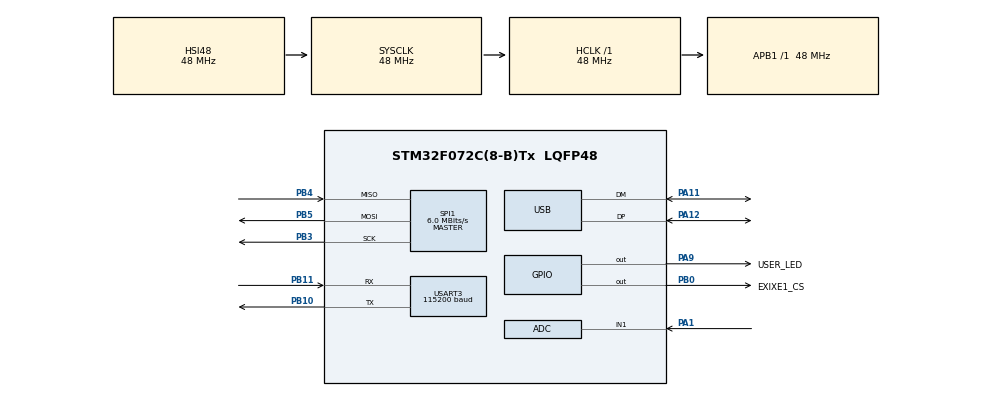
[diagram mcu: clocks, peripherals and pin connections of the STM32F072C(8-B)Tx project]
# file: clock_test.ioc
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ADC.ClockPrescaler=ADC_CLOCK_ASYNC_DIV1
ADC.ContinuousConvMode=DISABLE
ADC.DMAContinuousRequests=DISABLE
ADC.DataAlign=ADC_DATAALIGN_RIGHT
ADC.DiscontinuousConvMode=DISABLE
ADC.EOCSelection=ADC_EOC_SINGLE_CONV
ADC.EnableAnalogWatchDog=false
ADC.ExternalTrigConv=ADC_SOFTWARE_START
ADC.ExternalTrigConvEdge=ADC_EXTERNALTRIGCONVEDGE_NONE
ADC.LowPowerAutoPowerOff=DISABLE
ADC.LowPowerAutoWait=DISABLE
ADC.Overrun=ADC_OVR_DATA_PRESERVED
ADC.Resolution=ADC_RESOLUTION_12B
ADC.SamplingTime=ADC_SAMPLETIME_239CYCLES_5
ADC.ScanConvMode=ADC_SCAN_DIRECTION_FORWARD
FREERTOS.HEAP_NUMBER=1
FREERTOS.Tasks01=defaultTask,-3,64,StartDefaultTask,Default,NULL,Dynamic,NULL,NULL
FREERTOS.configENABLE_BACKWARD_COMPATIBILITY=0
FREERTOS.configMINIMAL_STACK_SIZE=64
FREERTOS.configTOTAL_HEAP_SIZE=4096
FREERTOS.configUSE_MUTEXES=0
FREERTOS.configUSE_TASK_NOTIFICATIONS=0
Mcu.Family=STM32F0
Mcu.Name=STM32F072C(8-B)Tx
Mcu.Package=LQFP48
NVIC.TIM7_IRQn=true\:0\:0\:false\:false\:true\:false
NVIC.TimeBase=TIM7_IRQn
NVIC.TimeBaseIP=TIM7
NVIC.USB_IRQn=true\:3\:0\:false\:false\:true\:true
PA1.Mode=IN1
PA1.Signal=ADC_IN1
PA11.Mode=Device
PA11.Signal=USB_DM
PA12.Mode=Device
PA12.Signal=USB_DP
PA13.Mode=Serial_Wire
PA13.Signal=SYS_SWDIO
PA14.Mode=Serial_Wire
PA14.Signal=SYS_SWCLK
PA9.GPIO_Label=USER_LED
PA9.PinState=GPIO_PIN_SET
PA9.Signal=GPIO_Output
PB0.GPIO_Label=EXIXE1_CS
PB0.PinState=GPIO_PIN_SET
PB0.Signal=GPIO_Output
PB10.Mode=Asynchronous
PB10.Signal=USART3_TX
PB11.Mode=Asynchronous
PB11.Signal=USART3_RX
PB3.Mode=Full_Duplex_Master
PB3.Signal=SPI1_SCK
PB4.Mode=Full_Duplex_Master
PB4.Signal=SPI1_MISO
PB5.Mode=Full_Duplex_Master
PB5.Signal=SPI1_MOSI
ProjectManager.HeapSize=0x200
ProjectManager.StackSize=0x400
ProjectManager.TargetToolchain=MDK-ARM V5
RCC.AHBFreq_Value=48000000
RCC.APB1Freq_Value=48000000
RCC.APB1TimFreq_Value=48000000
RCC.HCLKFreq_Value=48000000
RCC.PLLMUL=RCC_PLL_MUL6
RCC.SYSCLKFreq_VALUE=48000000
RCC.SYSCLKSource=RCC_SYSCLKSOURCE_HSI48
SPI1.BaudRatePrescaler=SPI_BAUDRATEPRESCALER_8
SPI1.CalculateBaudRate=6.0 MBits/s
SPI1.DataSize=SPI_DATASIZE_8BIT
SPI1.Direction=SPI_DIRECTION_2LINES
SPI1.Mode=SPI_MODE_MASTER
SPI1.VirtualType=VM_MASTER
TIM2.Prescaler=47
USART3.BaudRate=115200
USART3.VirtualMode-Asynchronous=VM_ASYNC
USART3.WordLength=WORDLENGTH_8B
USB_DEVICE.CLASS_NAME_FS=CDC
USB_DEVICE.VirtualMode=Cdc
USB_DEVICE.VirtualModeFS=Cdc_FS
VP_FREERTOS_VS_ENABLE.Mode=Enabled
VP_SYS_VS_tim7.Mode=TIM7
VP_TIM2_VS_ClockSourceINT.Mode=Internal
VP_USB_DEVICE_VS_USB_DEVICE_CDC_FS.Mode=CDC_FS
board=clock_test

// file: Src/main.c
/**
  ******************************************************************************
  * File Name          : main.c
  * Description        : Main program body
  ******************************************************************************
  *
  * Copyright (c) 2017 STMicroelectronics International N.V.
  * All rights reserved.
  *
  * Redistribution and use in source and binary forms, with or without
  * modification, are permitted, provided that the following conditions are met:
  *
  * 1. Redistribution of source code must retain the above copyright notice,
  *    this list of conditions and the following disclaimer.
  * 2. Redistributions in binary form must reproduce the above copyright notice,
  *    this list of conditions and the following disclaimer in the documentation
  *    and/or other materials provided with the distribution.
  * 3. Neither the name of STMicroelectronics nor the names of other
  *    contributors to this software may be used to endorse or promote products
  *    derived from this software without specific written permission.
  * 4. This software, including modifications and/or derivative works of this
  *    software, must execute solely and exclusively on microcontroller or
  *    microprocessor devices manufactured by or for STMicroelectronics.
  * 5. Redistribution and use of this software other than as permitted under
  *    this license is void and will automatically terminate your rights under
  *    this license.
  *
  * THIS SOFTWARE IS PROVIDED BY STMICROELECTRONICS AND CONTRIBUTORS "AS IS"
  * AND ANY EXPRESS, IMPLIED OR STATUTORY WARRANTIES, INCLUDING, BUT NOT
  * LIMITED TO, THE IMPLIED WARRANTIES OF MERCHANTABILITY, FITNESS FOR A
  * PARTICULAR PURPOSE AND NON-INFRINGEMENT OF THIRD PARTY INTELLECTUAL PROPERTY
  * RIGHTS ARE DISCLAIMED TO THE FULLEST EXTENT PERMITTED BY LAW. IN NO EVENT
  * SHALL STMICROELECTRONICS OR CONTRIBUTORS BE LIABLE FOR ANY DIRECT, INDIRECT,
  * INCIDENTAL, SPECIAL, EXEMPLARY, OR CONSEQUENTIAL DAMAGES (INCLUDING, BUT NOT
  * LIMITED TO, PROCUREMENT OF SUBSTITUTE GOODS OR SERVICES; LOSS OF USE, DATA,
  * OR PROFITS; OR BUSINESS INTERRUPTION) HOWEVER CAUSED AND ON ANY THEORY OF
  * LIABILITY, WHETHER IN CONTRACT, STRICT LIABILITY, OR TORT (INCLUDING
  * NEGLIGENCE OR OTHERWISE) ARISING IN ANY WAY OUT OF THE USE OF THIS SOFTWARE,
  * EVEN IF ADVISED OF THE POSSIBILITY OF SUCH DAMAGE.
  *
  ******************************************************************************
  */
#include "main.h"
#include "stm32f0xx_hal.h"
#include "cmsis_os.h"
#include "usb_device.h"

/* USER CODE BEGIN Includes */
#include "shared.h"
#include "my_usb.h"
#include "helpers.h"
#include "my_tasks.h"
#include "delay_us.h"
/* USER CODE END Includes */

ADC_HandleTypeDef hadc;

SPI_HandleTypeDef hspi1;

TIM_HandleTypeDef htim2;

UART_HandleTypeDef huart3;

osThreadId defaultTaskHandle;

/* USER CODE BEGIN PV */
/* Private variables ---------------------------------------------------------*/

/* USER CODE END PV */

void SystemClock_Config(void);
void Error_Handler(void);
static void MX_GPIO_Init(void);
static void MX_SPI1_Init(void);
static void MX_USART3_UART_Init(void);
static void MX_ADC_Init(void);
static void MX_TIM2_Init(void);
void StartDefaultTask(void const * argument);

/* USER CODE BEGIN PFP */
/* Private function prototypes -----------------------------------------------*/

/* USER CODE END PFP */

/* USER CODE BEGIN 0 */
// int fputc(int ch, FILE *f)
// {
//   my_usb_putchar((uint8_t)ch);
//   return ch;
// }

int fputc(int ch, FILE *f)
{
    HAL_UART_Transmit(&huart3, (unsigned char *)&ch, 1, 100);
    return ch;
}
/* USER CODE END 0 */

int main(void)
{

  /* MCU Configuration----------------------------------------------------------*/

  /* Reset of all peripherals, Initializes the Flash interface and the Systick. */
  HAL_Init();

  /* Configure the system clock */
  SystemClock_Config();

  /* Initialize all configured peripherals */
  MX_GPIO_Init();
  MX_SPI1_Init();
  MX_USART3_UART_Init();
  MX_ADC_Init();
  MX_TIM2_Init();

  /* USER CODE BEGIN 2 */
  MX_USB_DEVICE_Init();
  my_usb_init();
  delay_us_init(&htim2);
  setup_task();
  /* USER CODE END 2 */

  /* Create the thread(s) */
  /* definition and creation of defaultTask */
  osThreadDef(defaultTask, StartDefaultTask, osPriorityIdle, 0, 64);
  defaultTaskHandle = osThreadCreate(osThread(defaultTask), NULL);

  /* USER CODE BEGIN RTOS_THREADS */
  osThreadDef(animation_task, animation_task_start, osPriorityNormal, 0, 128);
  osThreadCreate(osThread(animation_task), NULL);
  osThreadDef(test_task, test_task_start, osPriorityNormal, 0, 64);
  osThreadCreate(osThread(test_task), NULL);
  /* add threads, ... */
  /* USER CODE END RTOS_THREADS */

  /* Start scheduler */
  osKernelStart();

  /* We should never get here as control is now taken by the scheduler */

  /* Infinite loop */
  while (1)
  {

  }

}

/** System Clock Configuration
*/
void SystemClock_Config(void)
{

  RCC_OscInitTypeDef RCC_OscInitStruct;
  RCC_ClkInitTypeDef RCC_ClkInitStruct;
  RCC_PeriphCLKInitTypeDef PeriphClkInit;

    /**Initializes the CPU, AHB and APB busses clocks
    */
  RCC_OscInitStruct.OscillatorType = RCC_OSCILLATORTYPE_HSI14|RCC_OSCILLATORTYPE_HSI48;
  RCC_OscInitStruct.HSI48State = RCC_HSI48_ON;
  RCC_OscInitStruct.HSI14State = RCC_HSI14_ON;
  RCC_OscInitStruct.HSI14CalibrationValue = 16;
  RCC_OscInitStruct.PLL.PLLState = RCC_PLL_NONE;
  if (HAL_RCC_OscConfig(&RCC_OscInitStruct) != HAL_OK)
  {
    Error_Handler();
  }

    /**Initializes the CPU, AHB and APB busses clocks
    */
  RCC_ClkInitStruct.ClockType = RCC_CLOCKTYPE_HCLK|RCC_CLOCKTYPE_SYSCLK
                              |RCC_CLOCKTYPE_PCLK1;
  RCC_ClkInitStruct.SYSCLKSource = RCC_SYSCLKSOURCE_HSI48;
  RCC_ClkInitStruct.AHBCLKDivider = RCC_SYSCLK_DIV1;
  RCC_ClkInitStruct.APB1CLKDivider = RCC_HCLK_DIV1;

  if (HAL_RCC_ClockConfig(&RCC_ClkInitStruct, FLASH_LATENCY_1) != HAL_OK)
  {
    Error_Handler();
  }

  PeriphClkInit.PeriphClockSelection = RCC_PERIPHCLK_USB;
  PeriphClkInit.UsbClockSelection = RCC_USBCLKSOURCE_HSI48;

  if (HAL_RCCEx_PeriphCLKConfig(&PeriphClkInit) != HAL_OK)
  {
    Error_Handler();
  }

    /**Configure the Systick interrupt time
    */
  HAL_SYSTICK_Config(HAL_RCC_GetHCLKFreq()/1000);

    /**Configure the Systick
    */
  HAL_SYSTICK_CLKSourceConfig(SYSTICK_CLKSOURCE_HCLK);

  /* SysTick_IRQn interrupt configuration */
  HAL_NVIC_SetPriority(SysTick_IRQn, 3, 0);
}

/* ADC init function */
static void MX_ADC_Init(void)
{

  ADC_ChannelConfTypeDef sConfig;

    /**Configure the global features of the ADC (Clock, Resolution, Data Alignment and number of conversion)
    */
  hadc.Instance = ADC1;
  hadc.Init.ClockPrescaler = ADC_CLOCK_ASYNC_DIV1;
  hadc.Init.Resolution = ADC_RESOLUTION_12B;
  hadc.Init.DataAlign = ADC_DATAALIGN_RIGHT;
  hadc.Init.ScanConvMode = ADC_SCAN_DIRECTION_FORWARD;
  hadc.Init.EOCSelection = ADC_EOC_SINGLE_CONV;
  hadc.Init.LowPowerAutoWait = DISABLE;
  hadc.Init.LowPowerAutoPowerOff = DISABLE;
  hadc.Init.ContinuousConvMode = DISABLE;
  hadc.Init.DiscontinuousConvMode = DISABLE;
  hadc.Init.ExternalTrigConv = ADC_SOFTWARE_START;
  hadc.Init.ExternalTrigConvEdge = ADC_EXTERNALTRIGCONVEDGE_NONE;
  hadc.Init.DMAContinuousRequests = DISABLE;
  hadc.Init.Overrun = ADC_OVR_DATA_PRESERVED;
  if (HAL_ADC_Init(&hadc) != HAL_OK)
  {
    Error_Handler();
  }

    /**Configure for the selected ADC regular channel to be converted.
    */
  sConfig.Channel = ADC_CHANNEL_1;
  sConfig.Rank = ADC_RANK_CHANNEL_NUMBER;
  sConfig.SamplingTime = ADC_SAMPLETIME_239CYCLES_5;
  if (HAL_ADC_ConfigChannel(&hadc, &sConfig) != HAL_OK)
  {
    Error_Handler();
  }

}

/* SPI1 init function */
static void MX_SPI1_Init(void)
{

  hspi1.Instance = SPI1;
  hspi1.Init.Mode = SPI_MODE_MASTER;
  hspi1.Init.Direction = SPI_DIRECTION_2LINES;
  hspi1.Init.DataSize = SPI_DATASIZE_8BIT;
  hspi1.Init.CLKPolarity = SPI_POLARITY_LOW;
  hspi1.Init.CLKPhase = SPI_PHASE_1EDGE;
  hspi1.Init.NSS = SPI_NSS_SOFT;
  hspi1.Init.BaudRatePrescaler = SPI_BAUDRATEPRESCALER_8;
  hspi1.Init.FirstBit = SPI_FIRSTBIT_MSB;
  hspi1.Init.TIMode = SPI_TIMODE_DISABLE;
  hspi1.Init.CRCCalculation = SPI_CRCCALCULATION_DISABLE;
  hspi1.Init.CRCPolynomial = 7;
  hspi1.Init.CRCLength = SPI_CRC_LENGTH_DATASIZE;
  hspi1.Init.NSSPMode = SPI_NSS_PULSE_ENABLE;
  if (HAL_SPI_Init(&hspi1) != HAL_OK)
  {
    Error_Handler();
  }

}

/* TIM2 init function */
static void MX_TIM2_Init(void)
{

  TIM_ClockConfigTypeDef sClockSourceConfig;
  TIM_MasterConfigTypeDef sMasterConfig;

  htim2.Instance = TIM2;
  htim2.Init.Prescaler = 47;
  htim2.Init.CounterMode = TIM_COUNTERMODE_UP;
  htim2.Init.Period = 4294967295;
  htim2.Init.ClockDivision = TIM_CLOCKDIVISION_DIV1;
  htim2.Init.AutoReloadPreload = TIM_AUTORELOAD_PRELOAD_DISABLE;
  if (HAL_TIM_Base_Init(&htim2) != HAL_OK)
  {
    Error_Handler();
  }

  sClockSourceConfig.ClockSource = TIM_CLOCKSOURCE_INTERNAL;
  if (HAL_TIM_ConfigClockSource(&htim2, &sClockSourceConfig) != HAL_OK)
  {
    Error_Handler();
  }

  sMasterConfig.MasterOutputTrigger = TIM_TRGO_RESET;
  sMasterConfig.MasterSlaveMode = TIM_MASTERSLAVEMODE_DISABLE;
  if (HAL_TIMEx_MasterConfigSynchronization(&htim2, &sMasterConfig) != HAL_OK)
  {
    Error_Handler();
  }

}

/* USART3 init function */
static void MX_USART3_UART_Init(void)
{

  huart3.Instance = USART3;
  huart3.Init.BaudRate = 115200;
  huart3.Init.WordLength = UART_WORDLENGTH_8B;
  huart3.Init.StopBits = UART_STOPBITS_1;
  huart3.Init.Parity = UART_PARITY_NONE;
  huart3.Init.Mode = UART_MODE_TX_RX;
  huart3.Init.HwFlowCtl = UART_HWCONTROL_NONE;
  huart3.Init.OverSampling = UART_OVERSAMPLING_16;
  huart3.Init.OneBitSampling = UART_ONE_BIT_SAMPLE_DISABLE;
  huart3.AdvancedInit.AdvFeatureInit = UART_ADVFEATURE_NO_INIT;
  if (HAL_UART_Init(&huart3) != HAL_OK)
  {
    Error_Handler();
  }

}

/** Configure pins as
        * Analog
        * Input
        * Output
        * EVENT_OUT
        * EXTI
*/
static void MX_GPIO_Init(void)
{

  GPIO_InitTypeDef GPIO_InitStruct;

  /* GPIO Ports Clock Enable */
  __HAL_RCC_GPIOC_CLK_ENABLE();
  __HAL_RCC_GPIOA_CLK_ENABLE();
  __HAL_RCC_GPIOB_CLK_ENABLE();

  /*Configure GPIO pin Output Level */
  HAL_GPIO_WritePin(OWIRE_DATA_GPIO_Port, OWIRE_DATA_Pin, GPIO_PIN_SET);

  /*Configure GPIO pin Output Level */
  HAL_GPIO_WritePin(EXIXE1_CS_GPIO_Port, EXIXE1_CS_Pin, GPIO_PIN_SET);

  /*Configure GPIO pin Output Level */
  HAL_GPIO_WritePin(USER_LED_GPIO_Port, USER_LED_Pin, GPIO_PIN_SET);

  /*Configure GPIO pin : OWIRE_DATA_Pin */
  GPIO_InitStruct.Pin = OWIRE_DATA_Pin;
  GPIO_InitStruct.Mode = GPIO_MODE_OUTPUT_OD;
  GPIO_InitStruct.Pull = GPIO_NOPULL;
  GPIO_InitStruct.Speed = GPIO_SPEED_FREQ_LOW;
  HAL_GPIO_Init(OWIRE_DATA_GPIO_Port, &GPIO_InitStruct);

  /*Configure GPIO pin : EXIXE1_CS_Pin */
  GPIO_InitStruct.Pin = EXIXE1_CS_Pin;
  GPIO_InitStruct.Mode = GPIO_MODE_OUTPUT_PP;
  GPIO_InitStruct.Pull = GPIO_NOPULL;
  GPIO_InitStruct.Speed = GPIO_SPEED_FREQ_LOW;
  HAL_GPIO_Init(EXIXE1_CS_GPIO_Port, &GPIO_InitStruct);

  /*Configure GPIO pin : USER_LED_Pin */
  GPIO_InitStruct.Pin = USER_LED_Pin;
  GPIO_InitStruct.Mode = GPIO_MODE_OUTPUT_PP;
  GPIO_InitStruct.Pull = GPIO_NOPULL;
  GPIO_InitStruct.Speed = GPIO_SPEED_FREQ_LOW;
  HAL_GPIO_Init(USER_LED_GPIO_Port, &GPIO_InitStruct);

}

/* StartDefaultTask function */
void StartDefaultTask(void const * argument)
{

  /* USER CODE BEGIN 5 */
  /* Infinite loop */
  for(;;)
  {
    osDelay(500);
  }
  /* USER CODE END 5 */
}

void HAL_TIM_PeriodElapsedCallback(TIM_HandleTypeDef *htim)
{
  if (htim->Instance == TIM7) {
    HAL_IncTick();
  }
}

void Error_Handler(void)
{
  while(1)
  {
  }
}

/************************ (C) COPYRIGHT STMicroelectronics *****END OF FILE****/
